VERSION ""

NS_ :

BS_:

BU_: RX72N CANalyzer

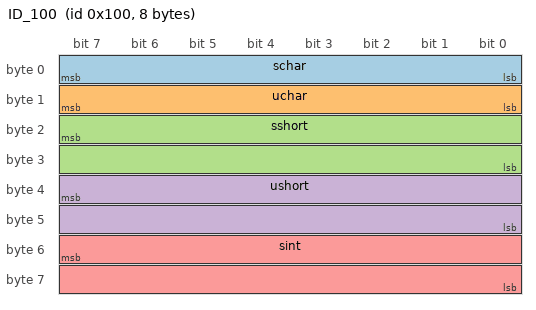
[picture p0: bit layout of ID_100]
BO_ 256 ID_100: 8 RX72N
 SG_ schar : 0|8@1- (1,0) [-128|127] "" CANalyzer
 SG_ uchar : 8|8@1+ (1,0) [0|255] "" CANalyzer
 SG_ sshort : 23|16@0- (1,0) [-32768|32767] "" CANalyzer
 SG_ ushort : 39|16@0+ (1,0) [0|65535] "" CANalyzer
 SG_ sint : 55|16@0- (1,0) [-32768|32767] "" CANalyzer

BO_ 257 ID_101: 8 RX72N
 SG_ uint : 7|16@0+ (1,0) [0|65535] "" CANalyzer
 SG_ slong : 23|32@0- (1,0) [-2147483648|2147483647] "" CANalyzer

BO_ 258 ID_102: 8 RX72N
 SG_ ulong : 7|32@0+ (1,0) [0|4294967295] "" CANalyzer

CM_ BO_ 256 "Data layout: data[0]=schar, data[1]=uchar, data[2..3]=sshort, data[4..5]=ushort, data[6..7]=lower 16 bits of sint.";
CM_ BO_ 257 "Data layout: data[0..1]=uint, data[2..5]=slong. data[6..7] is not assigned before transmission.";
CM_ BO_ 258 "Data layout: data[0..3]=ulong. data[4..7] is not assigned before transmission.";
